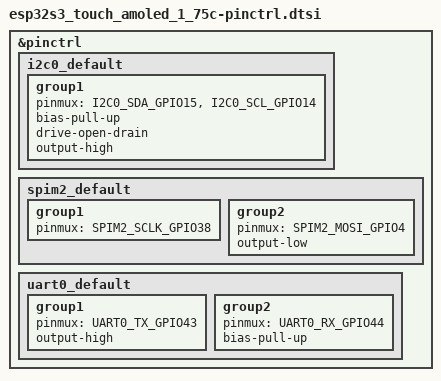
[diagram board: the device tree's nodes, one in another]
/*
 * Copyright (c) 2026 Hassan Naeem
 * SPDX-License-Identifier: Apache-2.0
 */

#include <zephyr/dt-bindings/pinctrl/esp32s3-pinctrl.h>

&pinctrl {
	i2c0_default: i2c0_default {
		group1 {
			pinmux = <I2C0_SDA_GPIO15>, <I2C0_SCL_GPIO14>;
			bias-pull-up;
			drive-open-drain;
			output-high;
		};
	};

	spim2_default: spim2_default {
		group1 {
			pinmux = <SPIM2_SCLK_GPIO38>;
		};

		group2 {
			pinmux = <SPIM2_MOSI_GPIO4>;
			output-low;
		};
	};

	uart0_default: uart0_default {
		group1 {
			pinmux = <UART0_TX_GPIO43>;
			output-high;
		};

		group2 {
			pinmux = <UART0_RX_GPIO44>;
			bias-pull-up;
		};
	};
};
